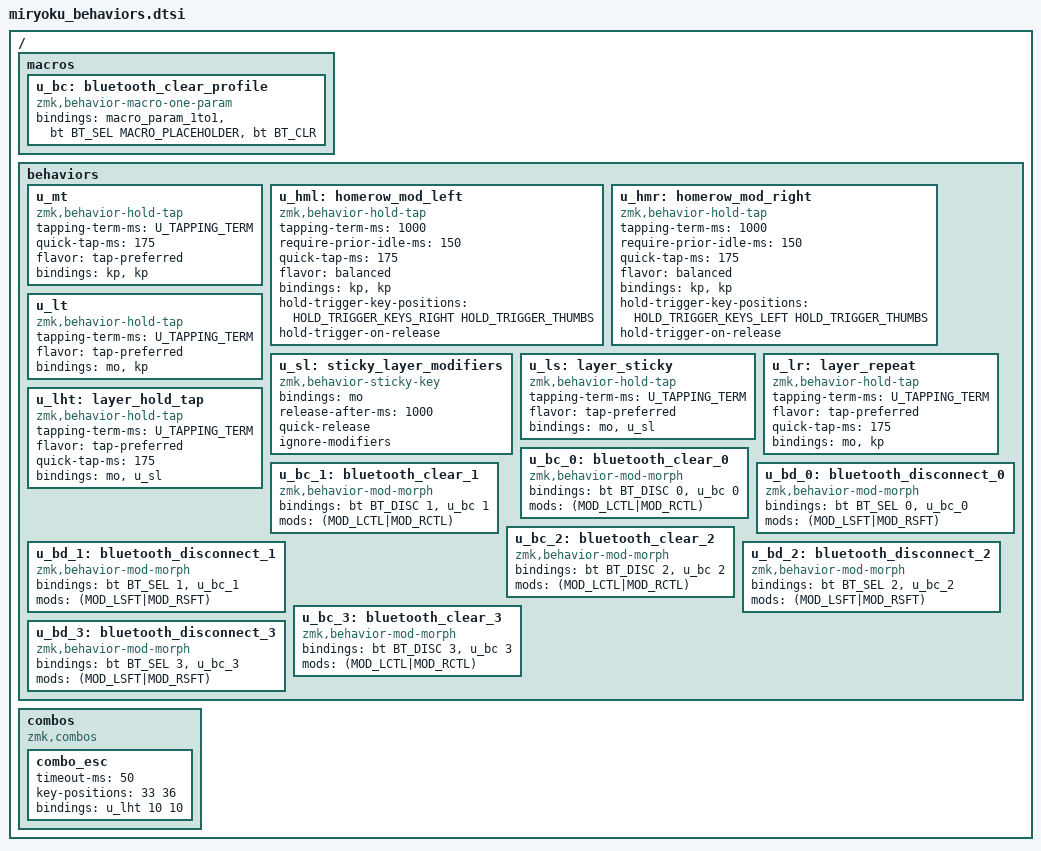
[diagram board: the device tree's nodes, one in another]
// Copyright 2022 Manna Harbour
// https://github.com/manna-harbour/miryoku

/ {
    macros {
        u_bc: bluetooth_clear_profile {
            compatible = "zmk,behavior-macro-one-param";
            #binding-cells = <1>;
            bindings = <&macro_param_1to1>,
                       <&bt BT_SEL MACRO_PLACEHOLDER>,
                       <&bt BT_CLR>;
        };
    };
};

/ {
  behaviors {
    u_mt: u_mt {
      compatible = "zmk,behavior-hold-tap";
      #binding-cells = <2>;
      tapping-term-ms = <U_TAPPING_TERM>;
      quick-tap-ms = <175>;
      flavor = "tap-preferred";
      bindings = <&kp>, <&kp>;
    };
    u_hml: homerow_mod_left {
      compatible = "zmk,behavior-hold-tap";
      #binding-cells = <2>;
      tapping-term-ms = <1000>;
      require-prior-idle-ms = <150>;
      quick-tap-ms = <175>;
      flavor = "balanced";
      bindings = <&kp>, <&kp>;
      hold-trigger-key-positions = <HOLD_TRIGGER_KEYS_RIGHT HOLD_TRIGGER_THUMBS>;
      hold-trigger-on-release;
    };
    u_hmr: homerow_mod_right {
      compatible = "zmk,behavior-hold-tap";
      #binding-cells = <2>;
      tapping-term-ms = <1000>;
      require-prior-idle-ms = <150>;
      quick-tap-ms = <175>;
      flavor = "balanced";
      bindings = <&kp>, <&kp>;
      hold-trigger-key-positions = <HOLD_TRIGGER_KEYS_LEFT HOLD_TRIGGER_THUMBS>;
      hold-trigger-on-release;
    };
    u_lt: u_lt {
      compatible = "zmk,behavior-hold-tap";
      #binding-cells = <2>;
      tapping-term-ms = <U_TAPPING_TERM>;
      flavor = "tap-preferred";
      bindings = <&mo>, <&kp>;
    };
    u_sl: sticky_layer_modifiers {
      compatible = "zmk,behavior-sticky-key";
      #binding-cells = <1>;
      bindings = <&mo>;
      release-after-ms = <1000>;
      quick-release;
      ignore-modifiers;
    };
    u_ls: layer_sticky {
      compatible = "zmk,behavior-hold-tap";
      #binding-cells = <2>;
      tapping-term-ms = <U_TAPPING_TERM>;
      flavor = "tap-preferred";
      bindings = <&mo>, <&u_sl>;
    };
    u_lr: layer_repeat {
      compatible = "zmk,behavior-hold-tap";
      #binding-cells = <2>;
      tapping-term-ms = <U_TAPPING_TERM>;
      flavor = "tap-preferred";
      quick-tap-ms = <175>;
      bindings = <&mo>, <&kp>;
    };
    u_lht: layer_hold_tap {
      compatible = "zmk,behavior-hold-tap";
      #binding-cells = <2>;
      tapping-term-ms = <U_TAPPING_TERM>;
      flavor = "tap-preferred";
      quick-tap-ms = <175>;
      bindings = <&mo>, <&u_sl>;
    };
    u_bc_0: bluetooth_clear_0 {
      compatible = "zmk,behavior-mod-morph";
      #binding-cells = <0>;
      bindings = <&bt BT_DISC 0>, <&u_bc 0>;
      mods = <(MOD_LCTL|MOD_RCTL)>;
    };
    u_bd_0: bluetooth_disconnect_0 {
      compatible = "zmk,behavior-mod-morph";
      #binding-cells = <0>;
      bindings = <&bt BT_SEL 0>, <&u_bc_0>;
      mods = <(MOD_LSFT|MOD_RSFT)>;
    };
    u_bc_1: bluetooth_clear_1 {
      compatible = "zmk,behavior-mod-morph";
      #binding-cells = <0>;
      bindings = <&bt BT_DISC 1>, <&u_bc 1>;
      mods = <(MOD_LCTL|MOD_RCTL)>;
    };
    u_bd_1: bluetooth_disconnect_1 {
      compatible = "zmk,behavior-mod-morph";
      #binding-cells = <0>;
      bindings = <&bt BT_SEL 1>, <&u_bc_1>;
      mods = <(MOD_LSFT|MOD_RSFT)>;
    };
    u_bc_2: bluetooth_clear_2 {
      compatible = "zmk,behavior-mod-morph";
      #binding-cells = <0>;
      bindings = <&bt BT_DISC 2>, <&u_bc 2>;
      mods = <(MOD_LCTL|MOD_RCTL)>;
    };
    u_bd_2: bluetooth_disconnect_2 {
      compatible = "zmk,behavior-mod-morph";
      #binding-cells = <0>;
      bindings = <&bt BT_SEL 2>, <&u_bc_2>;
      mods = <(MOD_LSFT|MOD_RSFT)>;
    };
    u_bc_3: bluetooth_clear_3 {
      compatible = "zmk,behavior-mod-morph";
      #binding-cells = <0>;
      bindings = <&bt BT_DISC 3>, <&u_bc 3>;
      mods = <(MOD_LCTL|MOD_RCTL)>;
    };
    u_bd_3: bluetooth_disconnect_3 {
      compatible = "zmk,behavior-mod-morph";
      #binding-cells = <0>;
      bindings = <&bt BT_SEL 3>, <&u_bc_3>;
      mods = <(MOD_LSFT|MOD_RSFT)>;
    };
  };
};

/ {
    combos {
        compatible = "zmk,combos";
        combo_esc {
            timeout-ms = <50>;
            key-positions = <33 36>;
            bindings = <&u_lht 10 10>;
        };
    };
};
